# R7FA2A2AD register map
Vendor: Renesas Electronics Corporation; Series: RA2A2; File version: 1.20.02
CPU: CM23 r1p0, little endian, MPU, no FPU, VTOR, 2 interrupt priority bits, 32 interrupts
Registers are 8-bit, read-write, reset 0x0 unless marked. A register's access mark holds for its fields unless they carry their own. Offsets are from the block's base; [hi:lo] are bit positions; {n}, {i} and the like mark numbered series; 'fields as' and 'values as' point back to an identical list.

## DBG — Debug Function
Base 0x4001B000
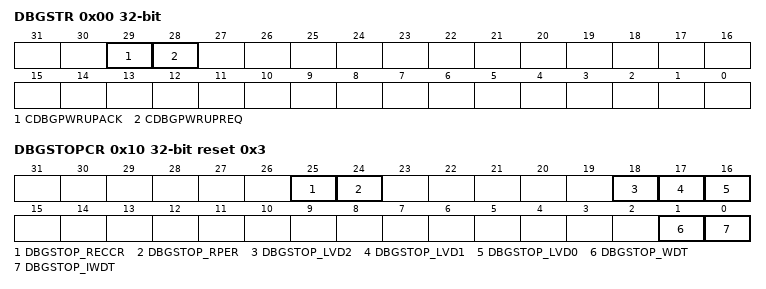
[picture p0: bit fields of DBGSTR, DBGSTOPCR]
0x00 DBGSTR 32-bit ro — Debug Status Register
  [29] CDBGPWRUPACK — Debug power-up acknowledge
    0=Debug power-up request is not acknowledged; 1=Debug power-up request is acknowledged
  [28] CDBGPWRUPREQ — Debug power-up request
    0=OCD is not requesting debug power up; 1=OCD is requesting debug power up
0x10 DBGSTOPCR 32-bit reset 0x3 — Debug Stop Control Register
  [25] DBGSTOP_RECCR — Mask bit for SRAM ECC error reset/interrupt
    0=Enable SRAM ECC error reset/interrupt; 1=Mask SRAM ECC error reset/interrupt
  [24] DBGSTOP_RPER — Mask bit for SRAM parity error reset/interrupt
    0=Enable SRAM parity error reset/interrupt; 1=Mask SRAM parity error reset/interrupt
  [18] DBGSTOP_LVD2 — Mask bit for LVD2 reset/interrupt
    0=Enable LVD2 reset/interrupt; 1=Mask LVD2 reset/interrupt
  [17] DBGSTOP_LVD1 — Mask bit for LVD1 reset/interrupt
    0=Enable LVD1 reset/interrupt; 1=Mask LVD1 reset/interrupt
  [16] DBGSTOP_LVD0 — Mask bit for LVD0 reset
    0=Enable LVD0 reset; 1=Mask LVD0 reset
  [1] DBGSTOP_WDT — Mask bit for WDT reset/interrupt in the OCD run mode
    0=Enable WDT reset/interrupt; 1=Mask WDT reset/interrupt and stop WDT counter
  [0] DBGSTOP_IWDT — Mask bit for IWDT reset/interrupt in the OCD run mode
    0=Enable IWDT reset/interrupt; 1=Mask IWDT reset/interrupt and stop IWDT counter

## PORT0 — Port 0 Control Registers
Base 0x40040000
Same registers: PORT3 0x40040060, PORT4 0x40040080, PORT5 0x400400A0, PORT6 0x400400C0
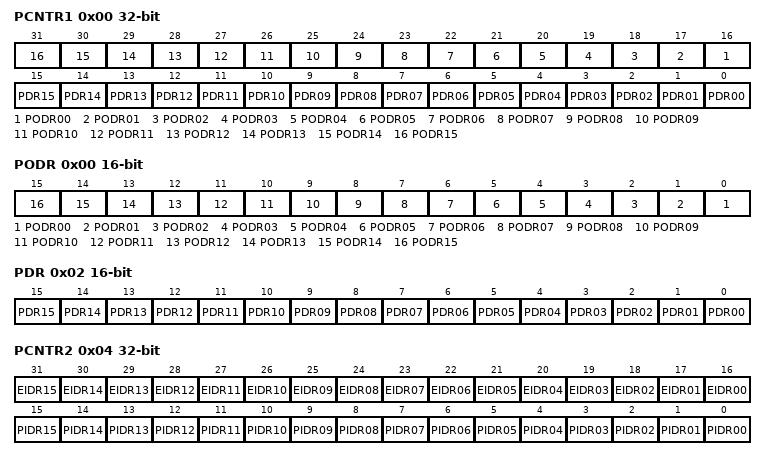
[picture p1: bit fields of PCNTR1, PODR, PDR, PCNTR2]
0x00 PCNTR1 32-bit — Port Control Register 1
  [n+16] PODR{n:02} (n=0..15) — Pmn Output Data
    0=Low output; 1=High output
  [n] PDR{n:02} (n=0..15) — Pmn Direction
    0=Input (functions as an input pin); 1=Output (functions as an output pin)
0x00 PODR 16-bit (alternate view of PCNTR1) — Port Control Register 1
  [all] fields
    0=Low output; 1=High output
  [n] PODR{n:02} (n=0..15) — Pmn Output Data
0x02 PDR 16-bit (alternate view of PCNTR1) — Port Control Register 1
  [all] fields
    values as PCNTR1.PDR00
  [n] PDR{n:02} (n=0..15) — Pmn Direction
0x04 PCNTR2 32-bit ro (reset mask 0xFFFF0000) — Port Control Register 2
  [n+16] EIDR{n:02} (n=0..15) — Port Event Input Data
    0=Low input; 1=High input
  [n] PIDR{n:02} (n=0..15) — Pmn State
    0=Low level; 1=High level
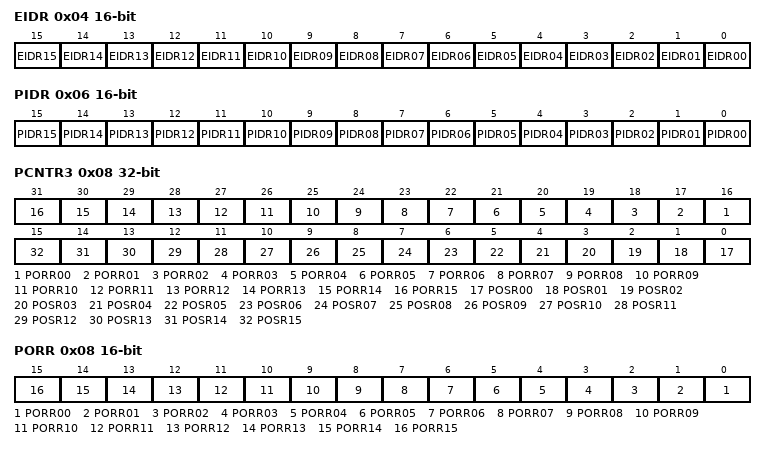
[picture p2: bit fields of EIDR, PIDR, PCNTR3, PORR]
0x04 EIDR 16-bit ro (alternate view of PCNTR2) — Port Control Register 2
  [all] fields
    0=Low input; 1=High input
  [n] EIDR{n:02} (n=0..15) — Port Event Input Data
0x06 PIDR 16-bit ro reset not defined (alternate view of PCNTR2) — Port Control Register 2
  [all] fields
    0=Low level; 1=High level
  [n] PIDR{n:02} (n=0..15) — Pmn State
0x08 PCNTR3 32-bit wo — Port Control Register 3
  [n+16] PORR{n:02} (n=0..15) — Pmn Output Reset
    0=No effect on output; 1=Low output
  [n] POSR{n:02} (n=0..15) — Pmn Output Set
    0=No effect on output; 1=High output
0x08 PORR 16-bit wo (alternate view of PCNTR3) — Port Control Register 3
  [all] fields
    0=No effect on output; 1=Low output
  [n] PORR{n:02} (n=0..15) — Pmn Output Reset
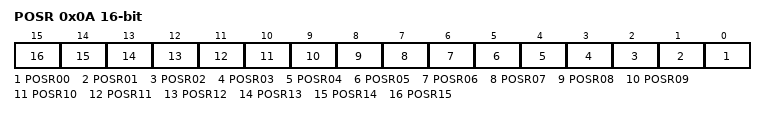
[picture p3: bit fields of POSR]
0x0A POSR 16-bit wo (alternate view of PCNTR3) — Port Control Register 3
  [all] fields
    0=No effect on output; 1=High output
  [n] POSR{n:02} (n=0..15) — Pmn Output Set

## PORT1 — Port 1 Control Registers
Base 0x40040020
Same registers: PORT2 0x40040040
Registers as PORT0; these are added or differ:
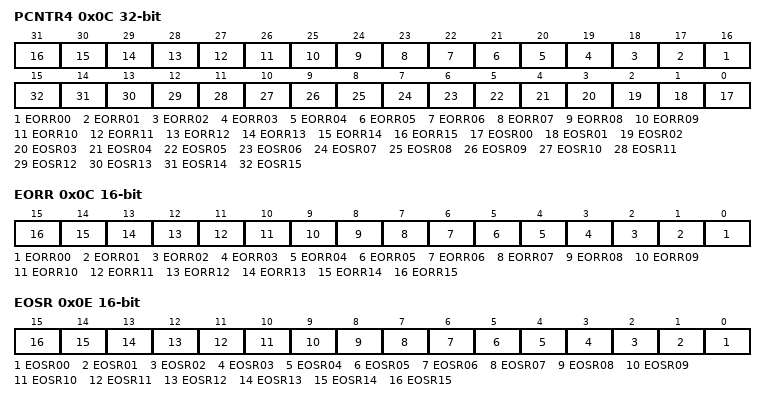
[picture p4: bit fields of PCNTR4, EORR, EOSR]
0x0C PCNTR4 32-bit — Port Control Register 4
  [n+16] EORR{n:02} (n=0..15) — Pmn Event Output Reset
    0=No effect on output; 1=Low output
  [n] EOSR{n:02} (n=0..15) — Pmn Event Output Set
    0=No effect on output; 1=High output
0x0C EORR 16-bit (alternate view of PCNTR4) — Port Control Register 4
  [all] fields
    0=No effect on output; 1=Low output
  [n] EORR{n:02} (n=0..15) — Pmn Event Output Reset
0x0E EOSR 16-bit (alternate view of PCNTR4) — Port Control Register 4
  [all] fields
    0=No effect on output; 1=High output
  [n] EOSR{n:02} (n=0..15) — Pmn Event Output Set
